VERSION ""

NS_ :

BS_:

BU_:

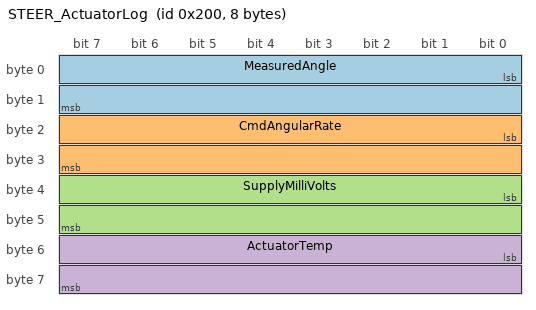
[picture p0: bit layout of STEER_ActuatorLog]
BO_ 512 STEER_ActuatorLog: 8 Vector__XXX
 SG_ MeasuredAngle : 0|16@1- (0.1,0) [0|0] "deg" Vector__XXX
 SG_ CmdAngularRate : 16|16@1- (0.1,0) [0|0] "deg/s" Vector__XXX
 SG_ SupplyMilliVolts : 32|16@1+ (1,0) [0|0] "mV" Vector__XXX
 SG_ ActuatorTemp : 48|16@1- (0.01,-40) [0|0] "degC" Vector__XXX

BA_DEF_  "BusType" STRING ;
BA_DEF_DEF_  "BusType" "CAN";
